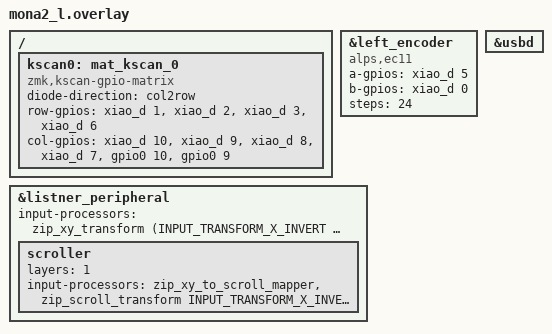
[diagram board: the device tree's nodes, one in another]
#include "mona2_kb.dtsi"
#include "mona2_pointer.dtsi"

/{

    kscan0: mat_kscan_0 {
    compatible = "zmk,kscan-gpio-matrix";
    diode-direction = "col2row";
    row-gpios
    = <&xiao_d 1 (GPIO_ACTIVE_HIGH | GPIO_PULL_DOWN)> 
    , <&xiao_d 2 (GPIO_ACTIVE_HIGH | GPIO_PULL_DOWN)> 
    , <&xiao_d 3 (GPIO_ACTIVE_HIGH | GPIO_PULL_DOWN)> 
    , <&xiao_d 6 (GPIO_ACTIVE_HIGH | GPIO_PULL_DOWN)> 			
    ;
    col-gpios
    = <&xiao_d 10 GPIO_ACTIVE_HIGH>
    , <&xiao_d 9 GPIO_ACTIVE_HIGH> 
    , <&xiao_d 8 GPIO_ACTIVE_HIGH> 
    , <&xiao_d 7 GPIO_ACTIVE_HIGH> 
    , <&gpio0 10 GPIO_ACTIVE_HIGH>
    , <&gpio0 9 GPIO_ACTIVE_HIGH>
    ;
  };
};

&left_encoder {
    compatible = "alps,ec11";
    a-gpios = <&xiao_d 5 (GPIO_ACTIVE_HIGH | GPIO_PULL_UP)>;
    b-gpios = <&xiao_d 0 (GPIO_ACTIVE_HIGH | GPIO_PULL_UP)>;
    steps = <24>;
    status = "okay";
};

&listner_peripheral {
    status = "okay";
    input-processors =  <&zip_xy_transform (INPUT_TRANSFORM_X_INVERT | INPUT_TRANSFORM_Y_INVERT)>;
    scroller {
        layers = <1>;
        input-processors = <&zip_xy_to_scroll_mapper>, <&zip_scroll_transform INPUT_TRANSFORM_X_INVERT>;
    };
};

zephyr_udc0: &usbd {
    status = "okay";
};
